# MDR1923VK014 register map
Vendor: Milandr; Series: ARMCM0; File version: 2.0
CPU: CM0 r0p0, little endian, no MPU, no FPU, 3 interrupt priority bits
Registers are 32-bit, read-write, reset 0x0 unless marked. A register's access mark holds for its fields unless they carry their own. Offsets are from the block's base; [hi:lo] are bit positions; {n}, {i} and the like mark numbered series; 'fields as' and 'values as' point back to an identical list.

## MDR_PORTA — PORTA
Base 0x40080000
Same registers: MDR_PORTB 0x40081000, MDR_PORTC 0x40082000, MDR_PORTD 0x40083000, MDR_PORTE 0x40084000
0x00 KEY — Key lock Register
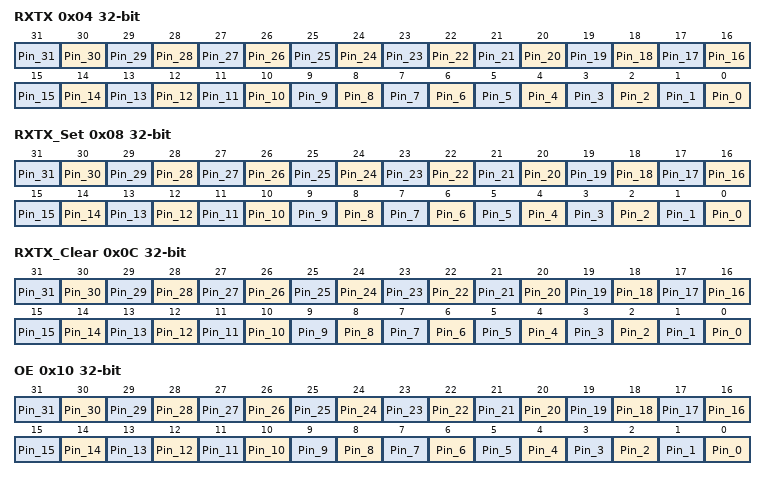
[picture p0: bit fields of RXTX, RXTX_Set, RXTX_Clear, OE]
0x04 RXTX — GPIO Pin Data Register
  [n] Pin_{n} (n=0..31) — Pin data value
    0=Low (LOW Level Voltage); 1=HIGH Level Voltage
0x08 RXTX_Set wo — Set RXTX Bits
  [n] Pin_{n} (n=0..31) — Set 1 to pin
    0=Off (Do nothing); 1=SET (Set pin)
0x0C RXTX_Clear wo — Clear RXTX Bits
  [n] Pin_{n} (n=0..31) — Set 0 to pin
    0=Off (Do nothing); 1=CLEAR (Clear pin)
0x10 OE ro — Pins Output Enable (Port function)
  [n] Pin_{n} (n=0..31) — Pin Output Enable
    0=IN (Input pin); 1=OUT (Output pin)
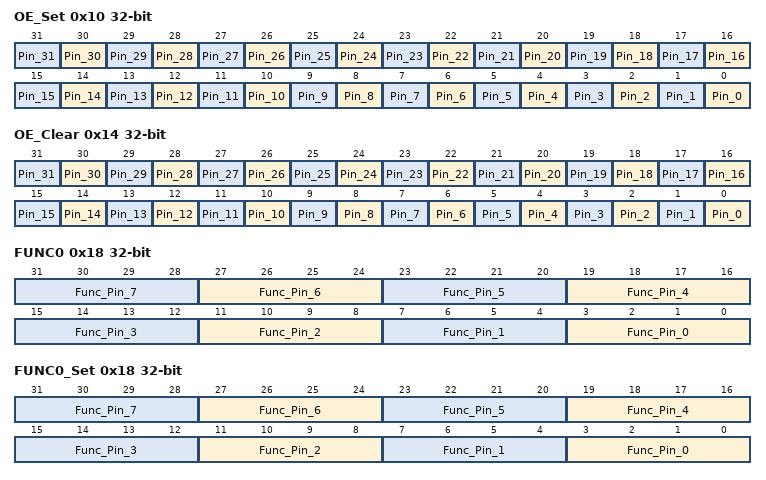
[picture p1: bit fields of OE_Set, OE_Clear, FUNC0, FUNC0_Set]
0x10 OE_Set wo — Set OE Pins
  fields as RXTX_Set
0x14 OE_Clear wo — Clear OE Pins
  fields as RXTX_Clear
0x18 FUNC0 ro — Pin0 - Pin7 Functions
  [4n+3:4n] Func_Pin_{n} (n=0..7) — Read SFUNC0 Register
    0=PORT (User Pin control); {v}=Func_{v} (Function periph pin control) (v=1..15)
0x18 FUNC0_Set wo — Set FUNC0 bits
  fields as FUNC0
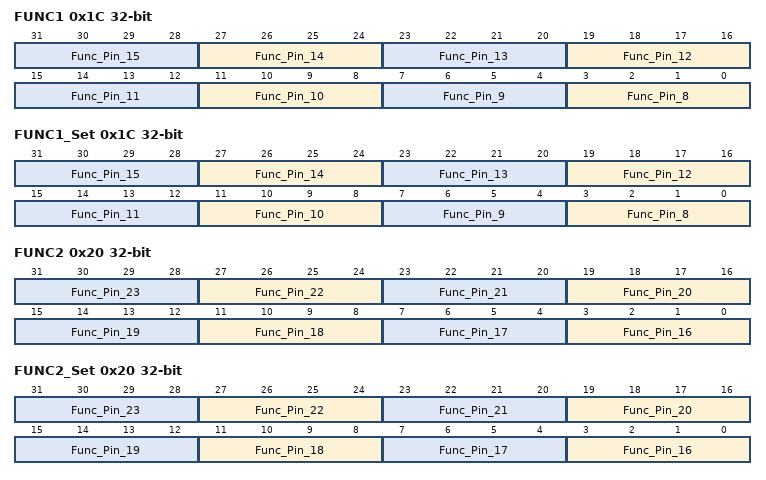
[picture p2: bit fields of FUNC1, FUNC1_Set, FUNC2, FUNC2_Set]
0x1C FUNC1 ro — Pin8 - Pin15 Functions
  [4n-29:4n-32] Func_Pin_{n} (n=8..15) — Read SFUNC1 Register
    values as FUNC0.Func_Pin_0
0x1C FUNC1_Set wo — Set FUNC1 bits
  fields as FUNC1
0x20 FUNC2 ro — Pin16 - Pin23 Functions
  [4n-61:4n-64] Func_Pin_{n} (n=16..23) — Read SFUNC2 Register
    values as FUNC0.Func_Pin_0
0x20 FUNC2_Set wo — Set FUNC2 bits
  fields as FUNC2
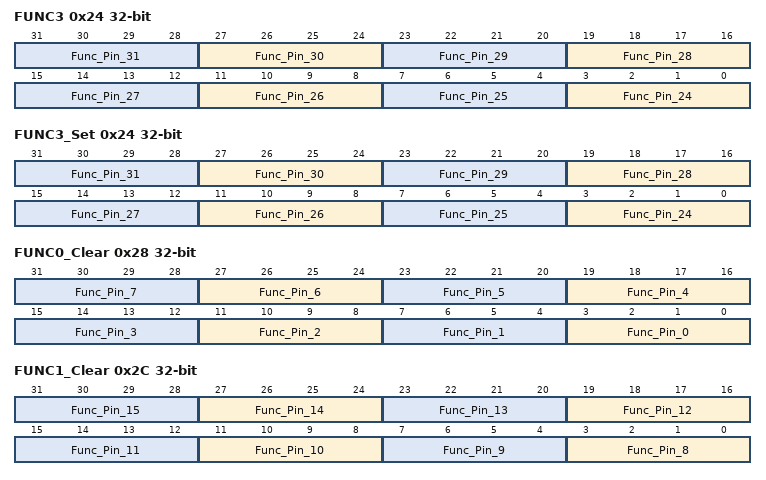
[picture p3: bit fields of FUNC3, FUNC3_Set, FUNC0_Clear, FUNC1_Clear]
0x24 FUNC3 ro — Pin24 - Pin31 Functions
  [4n-93:4n-96] Func_Pin_{n} (n=24..31) — Read SFUNC3 Register
    values as FUNC0.Func_Pin_0
0x24 FUNC3_Set wo — Set FUNC3 bits
  fields as FUNC3
0x28 FUNC0_Clear wo — Clear FUNC0 bits
  [4n+3:4n] Func_Pin_{n} (n=0..7)
    0=Inactive (No Action); {v}=ClrFunc_{v} (Function periph pin control) (v=1..14); 15=ClearToPort (Set Pin to Port function)
0x2C FUNC1_Clear wo — Clear FUNC1 bits
  [4n-29:4n-32] Func_Pin_{n} (n=8..15)
    values as FUNC0_Clear.Func_Pin_0
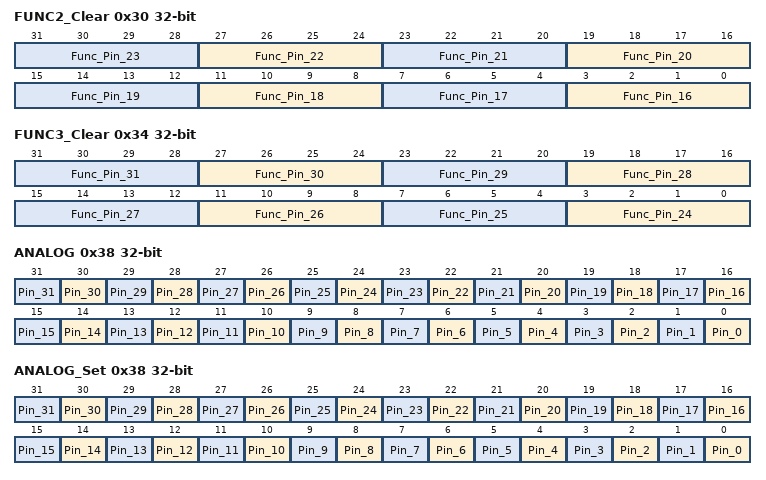
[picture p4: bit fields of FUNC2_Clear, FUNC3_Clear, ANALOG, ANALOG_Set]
0x30 FUNC2_Clear wo — Clear FUNC2 bits
  [4n-61:4n-64] Func_Pin_{n} (n=16..23)
    values as FUNC0_Clear.Func_Pin_0
0x34 FUNC3_Clear wo — Clear FUNC3 bits
  [4n-93:4n-96] Func_Pin_{n} (n=24..31)
    values as FUNC0_Clear.Func_Pin_0
0x38 ANALOG ro — Pins Digital Mode
  [n] Pin_{n} (n=0..31)
    0=Analog (Pin Analog signal); 1=Digital (Pin Digital signal)
0x38 ANALOG_Set wo — Set ANALOG bits
  fields as RXTX_Set
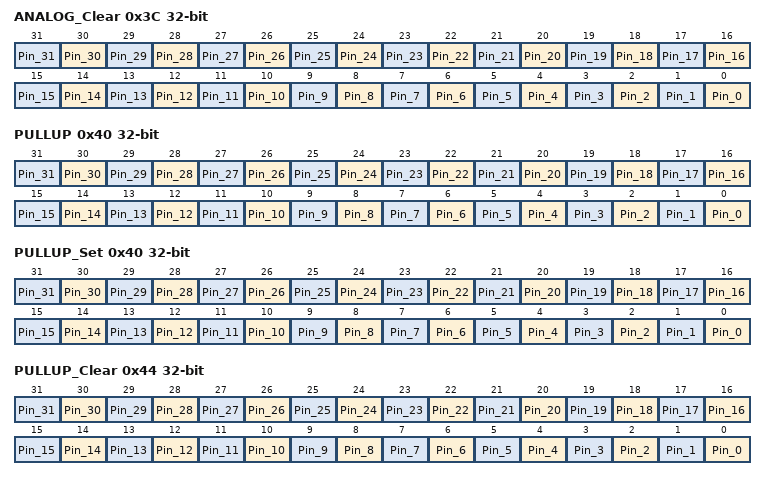
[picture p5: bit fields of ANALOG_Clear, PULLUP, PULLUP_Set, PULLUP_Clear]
0x3C ANALOG_Clear wo — Clear ANALOG bits
  fields as RXTX_Clear
0x40 PULLUP ro — Pins PullUP State
  [n] Pin_{n} (n=0..31) — Pins PullUp State
    0=Off (No pull selected); 1=UP (Pin pulled up to VDD)
0x40 PULLUP_Set wo — Set PULLUP bits
  fields as RXTX_Set
0x44 PULLUP_Clear wo — Clear PULLUP bits
  fields as RXTX_Clear
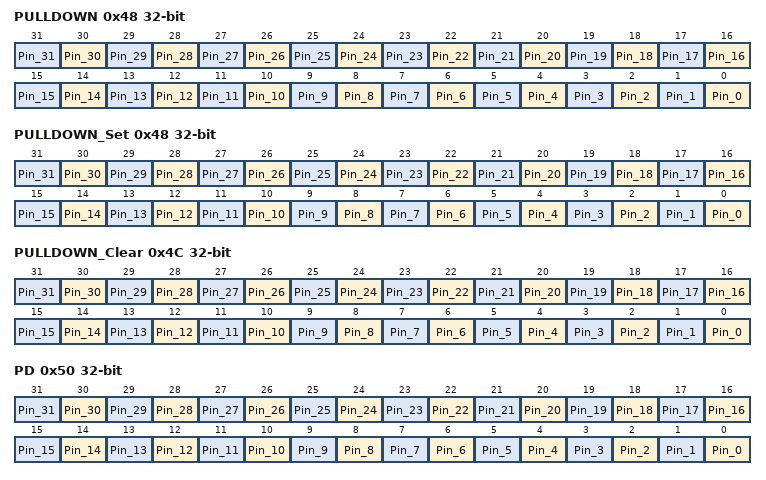
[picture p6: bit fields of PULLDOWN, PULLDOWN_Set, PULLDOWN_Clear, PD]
0x48 PULLDOWN ro — Pins PullDOWN State
  [n] Pin_{n} (n=0..31) — Pins PullUp State
    0=Off (No pull selected); 1=DOWN (Pin pulled up to GND)
0x48 PULLDOWN_Set wo — Set PULLDOWN bits
  fields as RXTX_Set
0x4C PULLDOWN_Clear wo — Clear PULLDOWN bits
  fields as RXTX_Clear
0x50 PD ro — Pins Driver Mode
  [n] Pin_{n} (n=0..31)
    0=Driver (Pull-Push driver); 1=OpenDrain (Drain Pulled Up Line)
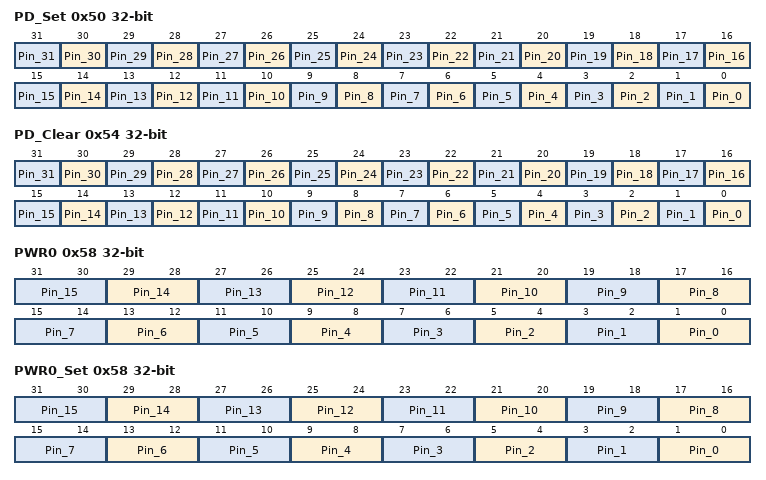
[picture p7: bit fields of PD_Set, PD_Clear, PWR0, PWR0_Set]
0x50 PD_Set wo — Set PD bits
  fields as RXTX_Set
0x54 PD_Clear wo — Clear PD bits
  fields as RXTX_Clear
0x58 PWR0 ro — Power of Pins 0 - 15
  [2n+1:2n] Pin_{n} (n=0..15) — Read SPWR Register
    0=Off (Level switch disabled); 1=Slow (Front ~300ns); 2=Fast (Front ~100ns); 3=MaxFast (Front ~10ns)
0x58 PWR0_Set wo — Set PWR0 bits
  fields as PWR0
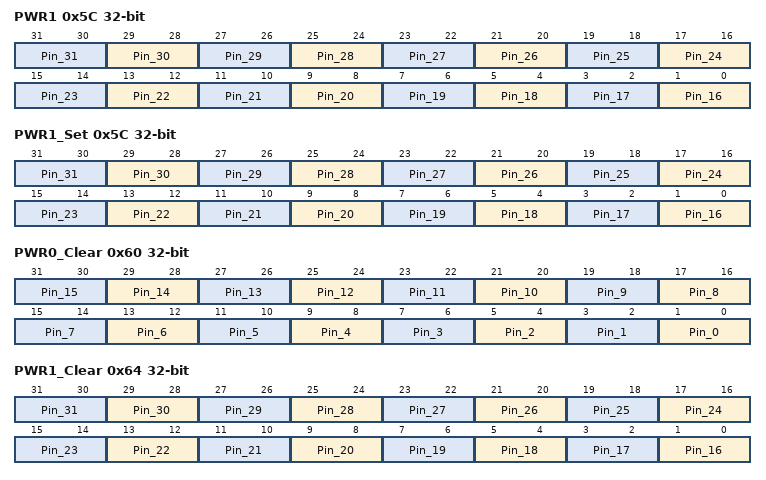
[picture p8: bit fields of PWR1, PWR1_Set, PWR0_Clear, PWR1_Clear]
0x5C PWR1 ro — Power of Pins 0 - 15
  [2n-31:2n-32] Pin_{n} (n=16..31) — Read SPWR1 Register
    values as PWR0.Pin_0
0x5C PWR1_Set wo — Set PWR1 bits
  fields as PWR1
0x60 PWR0_Clear wo — Clear PWR0 bits
  [2n+1:2n] Pin_{n} (n=0..15)
    0=Inactive (No action); 1=ClrSlow (Front ~300ns); 2=ClrFast (Front ~100ns); 3=ClrToOff (Pin Power Off)
0x64 PWR1_Clear wo — Clear PWR1 bits
  [2n-31:2n-32] Pin_{n} (n=16..31)
    values as PWR0_Clear.Pin_0
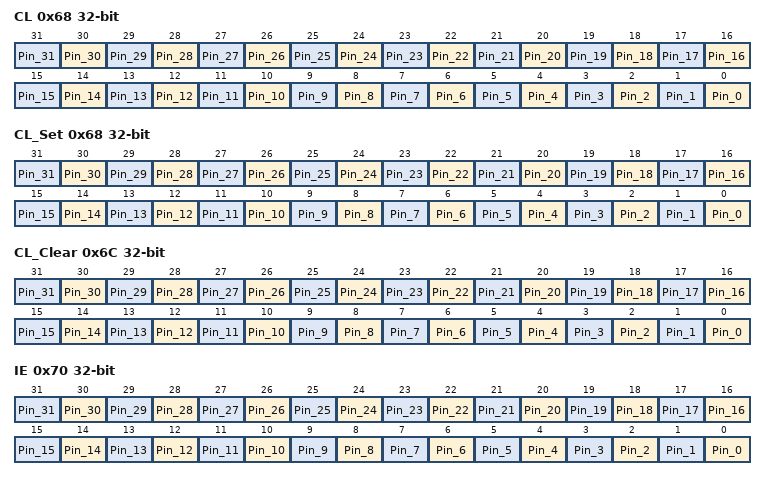
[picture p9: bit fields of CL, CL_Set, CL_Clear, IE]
0x68 CL ro — Pins Current Control enabled
  [n] Pin_{n} (n=0..31) — Read register SCL
    0=Off (Disable); 1=On (Enable)
0x68 CL_Set wo — Set CL bits
  fields as RXTX_Set
0x6C CL_Clear wo — Clear CL bits
  fields as RXTX_Clear
0x70 IE ro — Pin Level IRQ Enable
  [n] Pin_{n} (n=0..31) — Read register SIE
    0=Off (IRQ disabled); 1=On (IRQ enable)
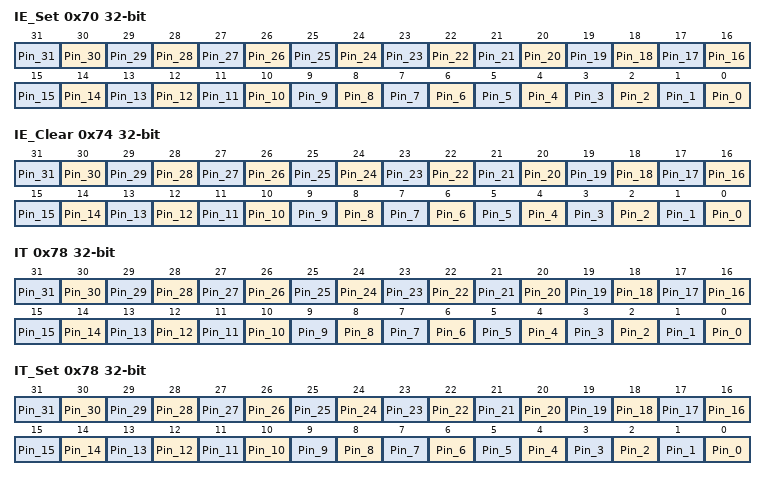
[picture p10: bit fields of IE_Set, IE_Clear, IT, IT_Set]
0x70 IE_Set wo — Set IE bits
  fields as RXTX_Set
0x74 IE_Clear wo — Clear IE bits
  fields as RXTX_Clear
0x78 IT ro — IRQ Level Select
  [n] Pin_{n} (n=0..31) — Read register SIT
    0=Low (IRQ by low level); 1=HIGH (IRQ by High level)
0x78 IT_Set wo — Set IT bits
  fields as RXTX_Set
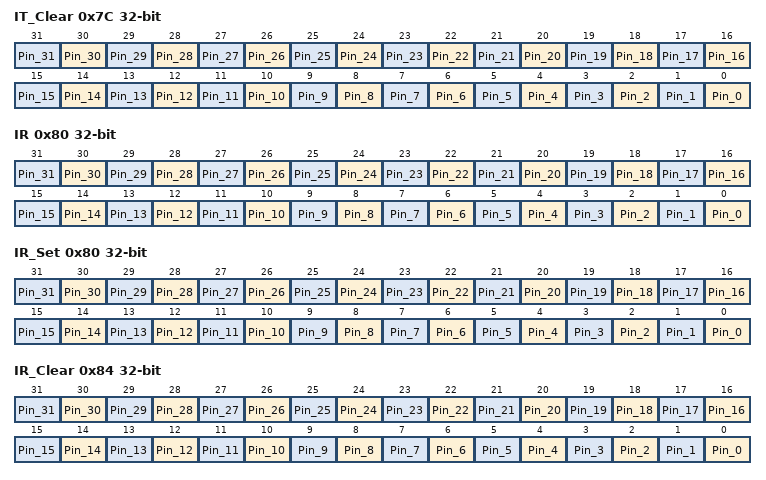
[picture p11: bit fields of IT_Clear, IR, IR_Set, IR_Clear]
0x7C IT_Clear wo — Clear IT bits
  fields as RXTX_Clear
0x80 IR ro — Read SIR Register
  [n] Pin_{n} (n=0..31) — Read register SIR
    0=Off (Inactive IRQ request); 1=On (Active IRQ request)
0x80 IR_Set wo — Set IR bits
  fields as RXTX_Set
0x84 IR_Clear wo — Clear IR bits
  fields as RXTX_Clear
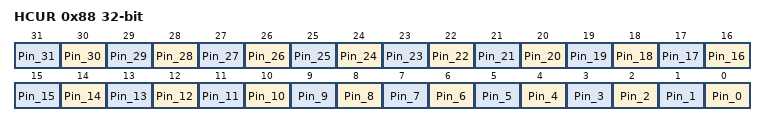
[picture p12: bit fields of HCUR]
0x88 HCUR — Pins' Overcurrent Status
  [n] Pin_{n} (n=0..31) — Register HCUR
    0=Off (Overcurrent is inactive); 1=On (Overcurrent is active)
